# FM33FG0XXA register map
File version: 1.0
CPU: SC000 r1p0, little endian, MPU, no FPU, 3 interrupt priority bits
Registers are 32-bit, read-only, reset 0x0 unless marked. A register's access mark holds for its fields unless they carry their own. Offsets are from the block's base; [hi:lo] are bit positions; {n}, {i} and the like mark numbered series.

## CAN — CAN module information
Base 0x40028000
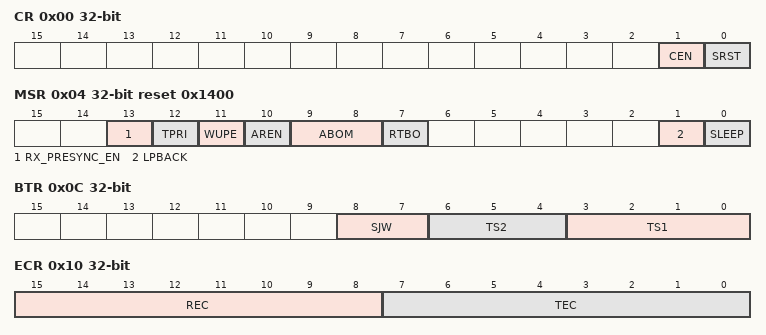
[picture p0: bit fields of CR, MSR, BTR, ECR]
0x00 CR rw — CAN Control Register
  [1] CEN — CEN field description
  [0] SRST — SRST field description
0x04 MSR rw reset 0x1400 — CAN mode select register
  [13] RX_PRESYNC_EN — RX_PRESYNC_EN field description
  [12] TPRI — TPRI field description
  [11] WUPE — WUPE field description
  [10] AREN — AREN field description
  [9:8] ABOM — ABOM field description
  [7] RTBO — RTBO field description
  [1] LPBACK — LPBACK field description
  [0] SLEEP — SLEEP field description
0x08 BRPR rw — CAN Baud rate Prescaler Register
  [7:0] BRP — BRP field description
0x0C BTR rw — CAN Bit Timing Register
  [8:7] SJW — SJW field description
  [6:4] TS2 — TS2 field description
  [3:0] TS1 — TS1 field description
0x10 ECR — CAN Error Counter Register
  [15:8] REC — REC field description
  [7:0] TEC — TEC field description
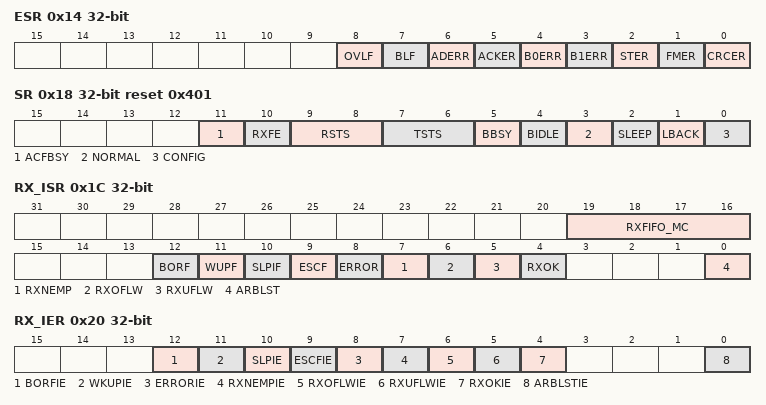
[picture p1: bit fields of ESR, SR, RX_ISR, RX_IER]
0x14 ESR rw — CAN Error Status Register
  [8] OVLF — OVLF field description
  [7] BLF — BLF field description
  [6] ADERR — ADERR field description
  [5] ACKER — ACKER field description
  [4] B0ERR — B0ERR field description
  [3] B1ERR — B1ERR field description
  [2] STER — STER field description
  [1] FMER — FMER field description
  [0] CRCER — CRCER field description
0x18 SR reset 0x401 — CAN Status Register
  [11] ACFBSY — ACFBSY field description
  [10] RXFE — RXFE field description
  [9:8] RSTS — RSTS field description
  [7:6] TSTS — TSTS field description
  [5] BBSY — BBSY field description
  [4] BIDLE — BIDLE field description
  [3] NORMAL — NORMAL field description
  [2] SLEEP — SLEEP field description
  [1] LBACK — LBACK field description
  [0] CONFIG — CONFIG field description
0x1C RX_ISR access per field — CAN Interrupt Status Register
  [19:16] RXFIFO_MC ro — RXFIFO_MC field description
  [12] BORF rw — BORF field description
  [11] WUPF rw — WUPF field description
  [10] SLPIF rw — SLPIF field description
  [9] ESCF rw — ESCF field description
  [8] ERROR rw — ERROR field description
  [7] RXNEMP rw — RXNEMP field description
  [6] RXOFLW rw — RXOFLW field description
  [5] RXUFLW rw — RXUFLW field description
  [4] RXOK rw — RXOK field description
  [0] ARBLST rw — ARBLST field description
0x20 RX_IER rw — CAN Interrupt Enable Register
  [12] BORFIE — BORFIE field description
  [11] WKUPIE — WKUPIE field description
  [10] SLPIE — SLPIE field description
  [9] ESCFIE — ESCFIE field description
  [8] ERRORIE — ERRORIE field description
  [7] RXNEMPIE — RXNEMPIE field description
  [6] RXOFLWIE — RXOFLWIE field description
  [5] RXUFLWIE — RXUFLWIE field description
  [4] RXOKIE — RXOKIE field description
  [0] ARBLSTIE — ARBLSTIE field description
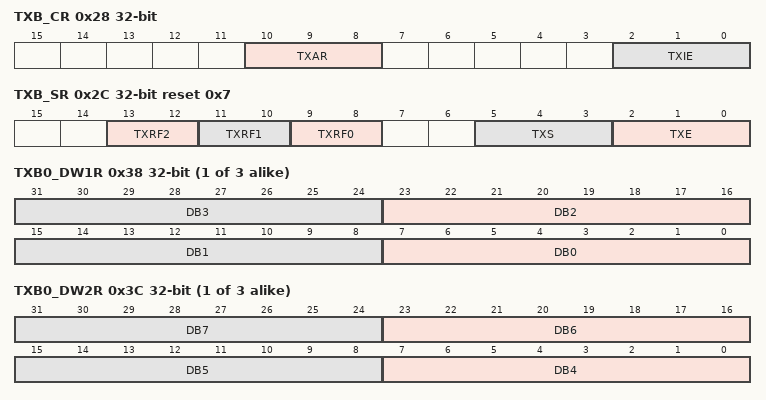
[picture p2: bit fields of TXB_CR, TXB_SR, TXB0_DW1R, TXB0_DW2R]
0x28 TXB_CR rw — CAN Transmit Buffer Control Register
  [10:8] TXAR — TXAR field description
  [2:0] TXIE — TXIE field description
0x2C TXB_SR access per field reset 0x7 — CAN Transmit Buffer Status Register
  [13:12] TXRF2 ro — TXRF2 field description
  [11:10] TXRF1 ro — TXRF1 field description
  [9:8] TXRF0 ro — TXRF0 field description
  [5:3] TXS ro — TXS field description
  [2:0] TXE rw — TXE field description
{0x30+0x10*i} TXB{i}_IDR wo (i=0..2) — CAN Transmit Buffer {i} ID Register
  [31:0] IDR — IDR field description
{0x34+0x10*i} TXB{i}_DLCR wo (i=0..2) — CAN Transmit Buffer {i} DLC Register
  [3:0] DLC — DLC field description
{0x38+0x10*i} TXB{i}_DW1R wo (i=0..2) — CAN Transmit Buffer {i} DataWord1 Register
  [8n+7:8n] DB{n} (n=0..3) — DB{n} field description
{0x3C+0x10*i} TXB{i}_DW2R wo (i=0..2) — CAN Transmit Buffer {i} DataWord2 Register
  [8n-25:8n-32] DB{n} (n=4..7) — DB{n} field description
0x60 AFCR rw — Acceptance Filter Control Register
  [15:0] UAF — UAF field description
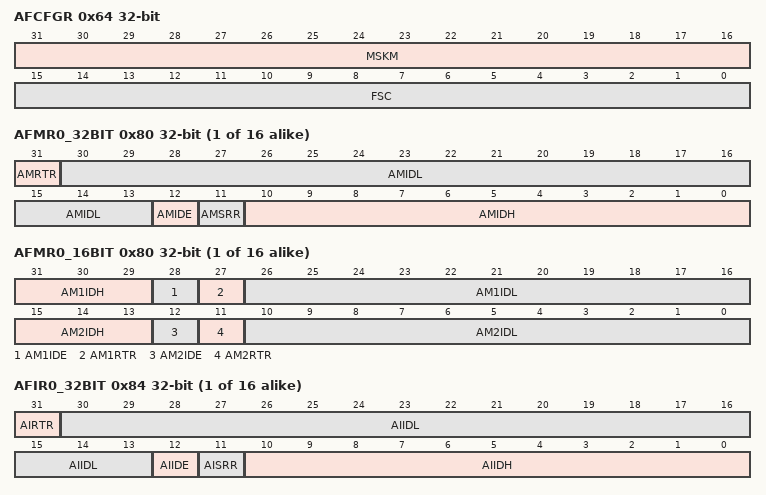
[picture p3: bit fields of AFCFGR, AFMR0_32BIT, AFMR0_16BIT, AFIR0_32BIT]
0x64 AFCFGR rw — Acceptance Filter Config Register
  [31:16] MSKM — MSKM field description
  [15:0] FSC — FSC field description
{0x80+8i} AFMR{i}_32BIT rw (i=0..15) — Acceptance Filter Mask Register{i}
  [31] AMRTR — AMRTR field description
  [30:13] AMIDL — AMIDL field description
  [12] AMIDE — AMIDE field description
  [11] AMSRR — AMSRR field description
  [10:0] AMIDH — AMIDH field description
{0x80+8i} AFMR{i}_16BIT rw (alternate view of AFMR{i}_32BIT) (i=0..15) — Acceptance Filter Mask Register{i}
  [31:29] AM1IDH — AM1IDH field description
  [28] AM1IDE — AM1IDE field description
  [27] AM1RTR — AM1RTR field description
  [26:16] AM1IDL — AM1IDL field description
  [15:13] AM2IDH — AM2IDH field description
  [12] AM2IDE — AM2IDE field description
  [11] AM2RTR — AM2RTR field description
  [10:0] AM2IDL — AM2IDL field description
{0x84+8i} AFIR{i}_32BIT rw (i=0..15) — Acceptance Filter ID Register{i}
  [31] AIRTR — AIRTR field description
  [30:13] AIIDL — AIIDL field description
  [12] AIIDE — AIIDE field description
  [11] AISRR — AISRR field description
  [10:0] AIIDH — AIIDH field description
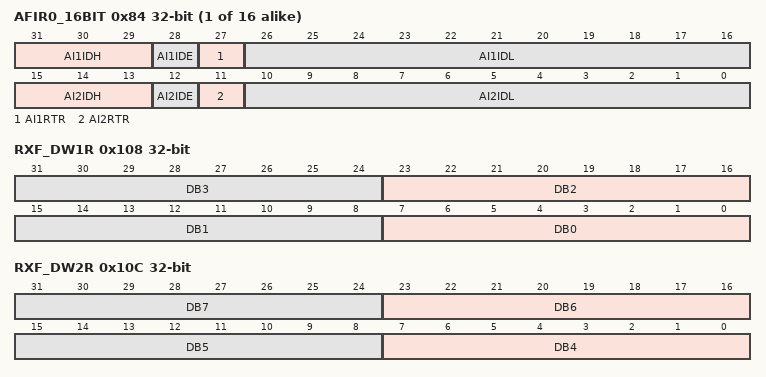
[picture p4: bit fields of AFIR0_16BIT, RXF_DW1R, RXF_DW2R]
{0x84+8i} AFIR{i}_16BIT rw (alternate view of AFIR{i}_32BIT) (i=0..15) — Acceptance Filter ID Register{i}
  [31:29] AI1IDH — AI1IDH field description
  [28] AI1IDE — AI1IDE field description
  [27] AI1RTR — AI1RTR field description
  [26:16] AI1IDL — AI1IDL field description
  [15:13] AI2IDH — AI2IDH field description
  [12] AI2IDE — AI2IDE field description
  [11] AI2RTR — AI2RTR field description
  [10:0] AI2IDL — AI2IDL field description
0x100 RXF_IDR wo — CAN RX FIFO ID Register
  [31:0] IDR — IDR field description
0x104 RXF_DLCR wo — CAN RX FIFO DLC Register
  [3:0] DLC — DLC field description
0x108 RXF_DW1R wo — CAN RX FIFO Data Word1 Register
  [8n+7:8n] DB{n} (n=0..3) — DB{n} field description
0x10C RXF_DW2R wo — CAN RX FIFO Data Word2 Register
  [8n-25:8n-32] DB{n} (n=4..7) — DB{n} field description
